# MSP430FR2433 register map
Vendor: msp430gen; File version: v0.4.0-29-g702f6f3-dirty
Registers are 16-bit, read-write, reset 0x0 unless marked. A register's access mark holds for its fields unless they carry their own. Offsets are from the block's base; [hi:lo] are bit positions; {n}, {i} and the like mark numbered series.

## SYS — SYS System Module
Base 0x00000140
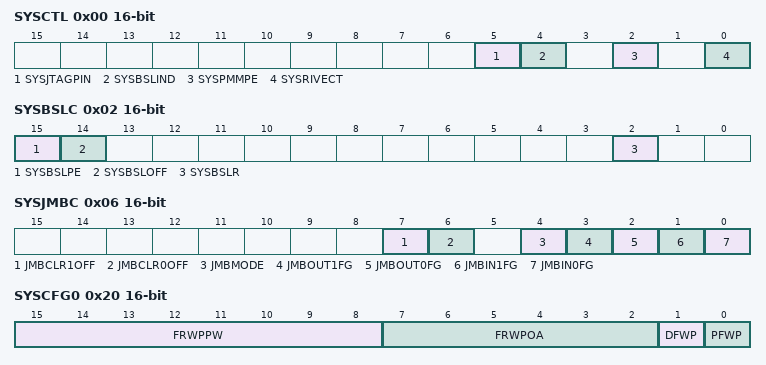
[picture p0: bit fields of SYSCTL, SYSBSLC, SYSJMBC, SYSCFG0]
0x00 SYSCTL — System control
  [5] SYSJTAGPIN — SYS - Dedicated JTAG pins enabled
    0=SHARED (Shared JTAG pins (JTAG mode selectable by JTAG/SBW sequence)); 1=DEDICATED (Dedicated JTAG pins (explicit 4-wire JTAG mode selection))
  [4] SYSBSLIND — SYS - TCK/RST indication detected
    0=CLR (No BSL entry sequence detected); 1=SET (BSL entry sequence detected)
  [2] SYSPMMPE — SYS - PMM access protect
    0=DIS (Access from anywhere in memory); 1=EN (Access only from the protected BSL segments)
  [0] SYSRIVECT — SYS - RAM based interrupt vectors
    0=FRAM (Interrupt vectors generated with end address TOP of lower 64KB of FRAM FFFFh); 1=RAM (Interrupt vectors generated with end address TOP of RAM)
0x02 SYSBSLC — Boot strap configuration area
  [15] SYSBSLPE — SYS - BSL Memory protection enabled
    0=NOTPROT (Area not protected. Read, program, and erase of BSL memory is possible.); 1=PROT (Area protected)
  [14] SYSBSLOFF — SYS - BSL Memory disabled
    0=ON (BSL memory is addressed when this area is read.); 1=OFF (BSL memory behaves like vacant memory. Reads cause 3FFFh to be read. Fetches cause JMP $ to be executed.)
  [2] SYSBSLR — SYS - RAM assigned to BSL
    0=NORAM (No RAM assigned to BSL area); 1=RAM (Lowest 16 bytes of RAM assigned to BSL)
0x06 SYSJMBC — JTAG mailbox control
  [7] JMBCLR1OFF — SYS - Incoming JTAG Mailbox 1 Flag auto-clear disable
  [6] JMBCLR0OFF — SYS - Incoming JTAG Mailbox 0 Flag auto-clear disable
  [4] JMBMODE — SYS - JMB 16/32 Bit Mode
  [3] JMBOUT1FG — SYS - Outgoing JTAG Mailbox 1 Flag
  [2] JMBOUT0FG — SYS - Outgoing JTAG Mailbox 0 Flag
  [1] JMBIN1FG — SYS - Incoming JTAG Mailbox 1 Flag
  [0] JMBIN0FG — SYS - Incoming JTAG Mailbox 0 Flag
0x08 SYSJMBI0 — JTAG mailbox input 0
0x0A SYSJMBI1 — JTAG mailbox input 1
0x0C SYSJMBO0 — JTAG mailbox output 0
0x0E SYSJMBO1 — JTAG mailbox output 1
0x18 SYSBERRIV — Bus Error vector generator
0x1A SYSUNIV — User NMI vector generator
  [15:0] SYSUNIV ro — User NMI vector
    2=NMI_PIN (NMIIFG NMI pin or SVSH event); 4=OSCILLATOR_FAULT (OFIFG oscillator fault)
0x1C SYSSNIV — System NMI vector generator
  [15:0] SYSSNIV ro — System NMI vector
    2=SVS_LOW_POWER_RESET_ENTRY; 4=FRAM_UNCORRECTABLE_BIT_ERROR (Uncorrectable FRAM bit error detection); 18=VACANT_MEMORY_ACCESS (VMAIFG vacant memory access); 20=JTAG_MAILBOX_IN (JMBINIFG JTAG mailbox input); 22=JTAG_MAILBOX_OUT (JMBOUTIFG JTAG mailbox output); 24=FRAM_CORRECTABLE_BIT_ERROR (Correctable FRAM bit error detection)
0x1E SYSRSTIV — Reset vector generator
  [15:0] SYSRSTIV ro — Reset interrupt vector
    2=BROWNOUT (Brownout (BOR)); 4=RESET_PIN (RSTIFG RST/NMI (BOR)); 6=SOFTWARE_BOR (PMMSWBOR software BOR (BOR)); 8=LPMX5_WAKE_UP (LPMx.5 wakeup (BOR)); 10=SECURITY_VIOLATION (Security violation (BOR)); 14=SVSH (SVSHIFG SVSH event (BOR)); 20=SOFTWARE_POR (PMMSWPOR software POR (POR)); 22=WATCHDOG_TIMEOUT (WDTIFG watchdog time-out (PUC)); 24=WATCHDOG_PASSWORD (WDTPW password violation (PUC)); 26=FRAM_PASSWORD (FRCTLPW password violation (PUC)); 28=FRAM_BIT_ERROR (Uncorrectable FRAM bit error detection); 30=PERIPHERAL_AREA_FETCH (Peripheral area fetch (PUC)); 32=PMM_PASSWORD (PMMPW PMM password violation (PUC)); 36=FLL_UNLOCK (FLL unlock (PUC))
0x20 SYSCFG0 — System Configuration 0
  [15:8] FRWPPW — FRAM protection password
    on read: 150=PASSWORD (Value always read from the SYSCFG0 password field) | on write: 165=PASSWORD (Value which must be written to the SYSCFG0 password field)
  [7:2] FRWPOA — Program FRAM Write Protection Offset
  [1] DFWP — Data FRAM Write Protection
  [0] PFWP — Program FRAM Write Protection
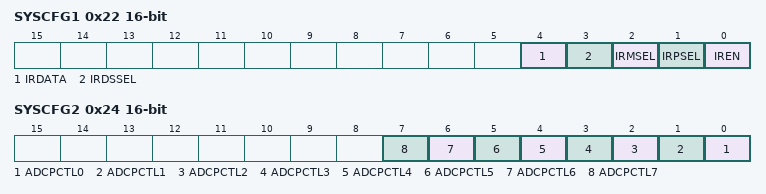
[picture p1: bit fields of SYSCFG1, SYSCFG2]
0x22 SYSCFG1 — System Configuration 1
  [4] IRDATA — Infrared enable
  [3] IRDSSEL — Infrared data source select
  [2] IRMSEL — Infrared mode select
    0=ASK (ASK mode); 1=FSK (FSK mode)
  [1] IRPSEL — Infrared polarity select
  [0] IREN — Infrared enable
0x24 SYSCFG2 — System Configuration 2
  [n] ADCPCTL{n} (n=0..7) — ADC input A{n} pin select
